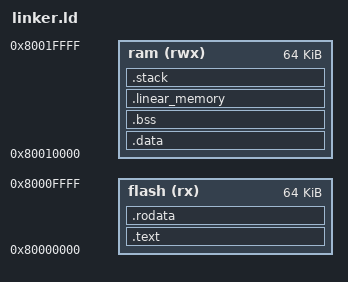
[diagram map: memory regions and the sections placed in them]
/* RISC-V Linker Script
 * Generated by synth-backend-riscv
 * Flash: 0x80000000 (64 KB), RAM: 0x80010000 (64 KB)
 * Linear memory: 4 KB, stack: 8 KB
 */

OUTPUT_ARCH("riscv")
ENTRY(_reset)

MEMORY {
  flash (rx)  : ORIGIN = 0x80000000, LENGTH = 64K
  ram   (rwx) : ORIGIN = 0x80010000, LENGTH = 64K
}

SECTIONS {
  .text : {
    KEEP(*(.text._reset))
    . = ALIGN(64);
    KEEP(*(.text._trap_entry))
    *(.text*)
  } > flash

  .rodata : {
    *(.rodata*)
    *(.srodata*)
    . = ALIGN(4);
    PROVIDE(_data_load = .);
  } > flash

  .data : AT(_data_load) {
    . = ALIGN(4);
    PROVIDE(_data_start = .);
    *(.data*)
    *(.sdata*)
    . = ALIGN(4);
    PROVIDE(_data_end = .);
  } > ram

  .bss (NOLOAD) : {
    . = ALIGN(4);
    PROVIDE(_bss_start = .);
    *(.bss*)
    *(.sbss*)
    *(COMMON)
    . = ALIGN(4);
    PROVIDE(_bss_end = .);
  } > ram

  /* Wasm linear memory — selector loads/stores use s11 = this */
  .linear_memory (NOLOAD) : ALIGN(16) {
    PROVIDE(__linear_memory_base = .);
    . += 4096;
    PROVIDE(__linear_memory_end = .);
  } > ram

  /* Stack grows down from end of RAM */
  .stack (NOLOAD) : ALIGN(16) {
    . += 8192;
    PROVIDE(_stack_top = .);
  } > ram

  /* Global pointer — points 0x800 above .sdata for short-form RV access */
  PROVIDE(__global_pointer$ = _data_start + 0x800);

}
